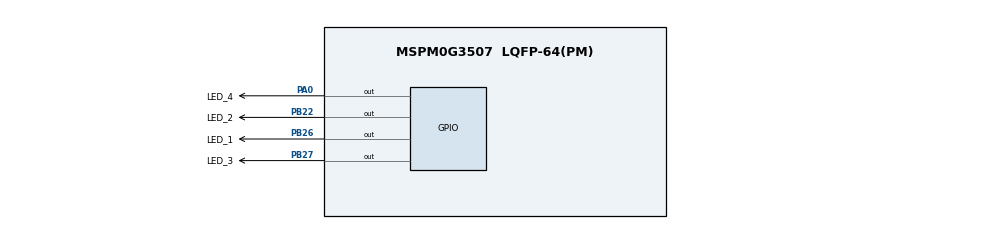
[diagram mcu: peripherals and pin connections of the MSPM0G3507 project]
/**
 * These arguments were used when this file was generated. They will be automatically applied on subsequent loads
 * via the GUI or CLI. Run CLI with '--help' for additional information on how to override these arguments.
 * @cliArgs --device "MSPM0G350X" --part "Default" --package "LQFP-64(PM)" --product "mspm0_sdk@2.04.00.06"
 * @v2CliArgs --device "MSPM0G3507" --package "LQFP-64(PM)" --product "mspm0_sdk@2.04.00.06"
 * @versions {"tool":"1.22.0+3893"}
 */

/**
 * Import the modules used in this configuration.
 */
const GPIO          = scripting.addModule("/ti/driverlib/GPIO", {}, false);
const GPIO1         = GPIO.addInstance();
const PWM           = scripting.addModule("/ti/driverlib/PWM", {}, false);
const PWM1          = PWM.addInstance();
const SYSCTL        = scripting.addModule("/ti/driverlib/SYSCTL");
const TIMER         = scripting.addModule("/ti/driverlib/TIMER", {}, false);
const TIMER1        = TIMER.addInstance();
const TIMER2        = TIMER.addInstance();
const ProjectConfig = scripting.addModule("/ti/project_config/ProjectConfig");

/**
 * Write custom configuration values to the imported modules.
 */
GPIO1.$name                             = "GPIO_GRP_0";
GPIO1.associatedPins.create(4);
GPIO1.associatedPins[0].$name           = "LED_1";
GPIO1.associatedPins[0].subOutputPolicy = "CLEAR";
GPIO1.associatedPins[0].pin.$assign     = "PB26";
GPIO1.associatedPins[1].$name           = "LED_2";
GPIO1.associatedPins[1].pin.$assign     = "PB22";
GPIO1.associatedPins[2].$name           = "LED_3";
GPIO1.associatedPins[2].pin.$assign     = "PB27";
GPIO1.associatedPins[3].$name           = "LED_4";
GPIO1.associatedPins[3].initialValue    = "SET";
GPIO1.associatedPins[3].pin.$assign     = "PA0";

const Board = scripting.addModule("/ti/driverlib/Board", {}, false);

PWM1.$name                       = "PWM_0";
PWM1.ccIndex                     = [0];
PWM1.clockSource                 = "LFCLK";
PWM1.timerStartTimer             = true;
PWM1.pwmMode                     = "EDGE_ALIGN_UP";
PWM1.event2ControllerInterruptEn = ["ZERO_EVENT"];
PWM1.interrupts                  = ["CC0_DN_EVENT","CC0_UP_EVENT","ZERO_EVENT"];
PWM1.timerCount                  = 256;
PWM1.PWM_CHANNEL_0.$name         = "ti_driverlib_pwm_PWMTimerCC0";
PWM1.PWM_CHANNEL_0.dutyCycle     = 50;
PWM1.ccp0PinConfig.$name         = "ti_driverlib_gpio_GPIOPinGeneric0";


TIMER1.timerClkSrc = "LFCLK";
TIMER1.timerMode   = "PERIODIC";
TIMER1.timerPeriod = "1000 ms";
TIMER1.interrupts  = ["ZERO"];
TIMER1.$name       = "SECOND_TICKER";

TIMER2.$name              = "PULSE_TIMER";
TIMER2.timerClkDiv        = 8;
TIMER2.interrupts         = ["ZERO"];
TIMER2.timerMode          = "PERIODIC";
TIMER2.timerPeriod        = "50 ms";
TIMER2.peripheral.$assign = "TIMG12";

ProjectConfig.deviceSpin = "MSPM0G3507";

/**
 * Pinmux solution for unlocked pins/peripherals. This ensures that minor changes to the automatic solver in a future
 * version of the tool will not impact the pinmux you originally saw.  These lines can be completely deleted in order to
 * re-solve from scratch.
 */
Board.peripheral.$suggestSolution          = "DEBUGSS";
Board.peripheral.swclkPin.$suggestSolution = "PA20";
Board.peripheral.swdioPin.$suggestSolution = "PA19";
PWM1.peripheral.$suggestSolution           = "TIMA1";
PWM1.peripheral.ccp0Pin.$suggestSolution   = "PA10";
SYSCTL.peripheral.$suggestSolution         = "SYSCTL";
TIMER1.peripheral.$suggestSolution         = "TIMA0";
